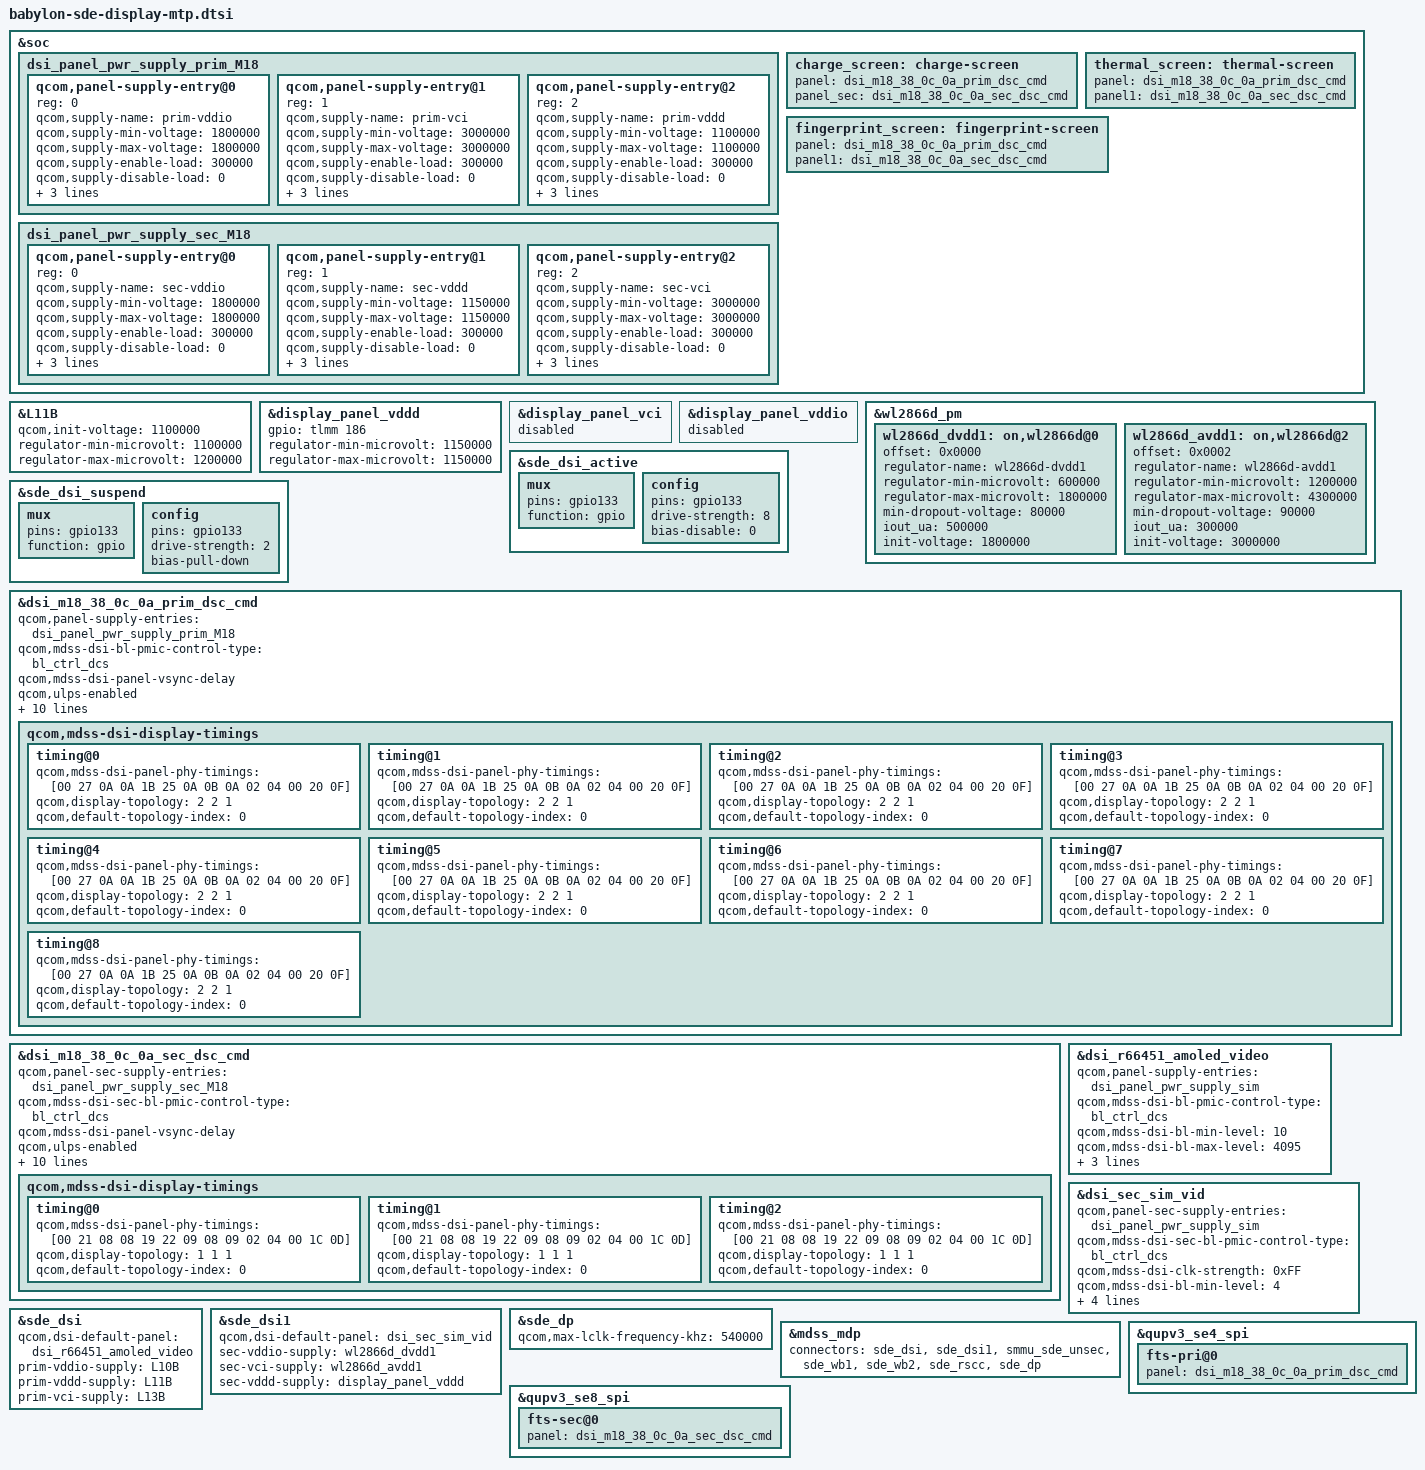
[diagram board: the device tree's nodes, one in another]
#include "kalama-sde-display.dtsi"
#include "dsi-panel-m18-38-0c-0a-prim-dsc-cmd.dtsi"
#include "dsi-panel-m18-38-0c-0a-sec-dsc-cmd.dtsi"

&soc {
	dsi_panel_pwr_supply_prim_M18: dsi_panel_pwr_supply_prim_M18 {
		qcom,panel-supply-entry@0 {
			reg = <0>;
			qcom,supply-name = "prim-vddio";
			qcom,supply-min-voltage = <1800000>;
			qcom,supply-max-voltage = <1800000>;
			qcom,supply-enable-load = <300000>;
			qcom,supply-disable-load = <0>;
			qcom,supply-post-on-sleep = <1>;
			qcom,supply-post-off-sleep = <0>;
			qcom,supply-pre-off-sleep = <15>;
		};
		qcom,panel-supply-entry@1 {
			reg = <1>;
			qcom,supply-name = "prim-vci";
			qcom,supply-min-voltage = <3000000>;
			qcom,supply-max-voltage = <3000000>;
			qcom,supply-enable-load = <300000>;
			qcom,supply-disable-load = <0>;
			qcom,supply-post-on-sleep = <1>;
			qcom,supply-post-off-sleep = <0>;
			qcom,supply-pre-off-sleep = <15>;
		};
		qcom,panel-supply-entry@2 {
			reg = <2>;
			qcom,supply-name = "prim-vddd";
			qcom,supply-min-voltage = <1100000>;
			qcom,supply-max-voltage = <1100000>;
			qcom,supply-enable-load = <300000>;
			qcom,supply-disable-load = <0>;
			qcom,supply-post-on-sleep = <1>;
			qcom,supply-post-off-sleep = <0>;
			qcom,supply-pre-off-sleep = <15>;
		};
	};

	dsi_panel_pwr_supply_sec_M18: dsi_panel_pwr_supply_sec_M18 {
		qcom,panel-supply-entry@0 {
			reg = <0>;
			qcom,supply-name = "sec-vddio";
			qcom,supply-min-voltage = <1800000>;
			qcom,supply-max-voltage = <1800000>;
			qcom,supply-enable-load = <300000>;
			qcom,supply-disable-load = <0>;
			qcom,supply-post-on-sleep = <1>;
			qcom,supply-post-off-sleep = <0>;
			qcom,supply-pre-off-sleep = <15>;
		};
		qcom,panel-supply-entry@1 {
			reg = <1>;
			qcom,supply-name = "sec-vddd";
			qcom,supply-min-voltage = <1150000>;
			qcom,supply-max-voltage = <1150000>;
			qcom,supply-enable-load = <300000>;
			qcom,supply-disable-load = <0>;
			qcom,supply-post-on-sleep = <1>;
			qcom,supply-post-off-sleep = <0>;
			qcom,supply-pre-off-sleep = <15>;
		};
		qcom,panel-supply-entry@2 {
			reg = <2>;
			qcom,supply-name = "sec-vci";
			qcom,supply-min-voltage = <3000000>;
			qcom,supply-max-voltage = <3000000>;
			qcom,supply-enable-load = <300000>;
			qcom,supply-disable-load = <0>;
			qcom,supply-post-on-sleep = <1>;
			qcom,supply-post-off-sleep = <0>;
			qcom,supply-pre-off-sleep = <15>;
		};

	};
};

&L11B {
	qcom,init-voltage = <1100000>;
	regulator-min-microvolt = <1100000>;
	regulator-max-microvolt = <1200000>;
};

&display_panel_vddd {
	gpio = <&tlmm 186 0>;
	regulator-min-microvolt = <1150000>;
	regulator-max-microvolt = <1150000>;
};

&display_panel_vci {
	status = "disabled";
};

&display_panel_vddio {
	status = "disabled";
};

&wl2866d_pm {
	wl2866d_dvdd1:on,wl2866d@0{
		offset = /bits/ 16 <0x0000>;
		regulator-name ="wl2866d-dvdd1";
		regulator-min-microvolt = <600000>;
		regulator-max-microvolt = <1800000>;
		min-dropout-voltage = <80000>;
		iout_ua = <500000>;
		init-voltage = <1800000>;
	};

	wl2866d_avdd1:on,wl2866d@2{
		offset = /bits/ 16 <0x0002>;
		regulator-name ="wl2866d-avdd1";
		regulator-min-microvolt = <1200000>;
		regulator-max-microvolt = <4300000>;
		min-dropout-voltage = <90000>;
		iout_ua = <300000>;
		init-voltage = <3000000>;
	};
};

&sde_dsi_active {
	mux {
		pins = "gpio133";
		function = "gpio";
	};

	config {
		pins = "gpio133";
		drive-strength = <8>;   /* 8 mA */
		bias-disable = <0>;   /* no pull */
	};
};

&sde_dsi_suspend {
	mux {
		pins = "gpio133";
		function = "gpio";
	};

	config {
		pins = "gpio133";
		drive-strength = <2>;   /* 2 mA */
		bias-pull-down;         /* PULL DOWN */
	};
};

&dsi_m18_38_0c_0a_prim_dsc_cmd {
	qcom,panel-supply-entries = <&dsi_panel_pwr_supply_prim_M18>;
	qcom,mdss-dsi-bl-pmic-control-type = "bl_ctrl_dcs";
	qcom,mdss-dsi-panel-vsync-delay;
	qcom,ulps-enabled;
	qcom,dsi-select-clocks = "pll_byte_clk0", "pll_dsi_clk0";
	qcom,mdss-dsi-clk-strength = <0xFF>;
	qcom,mdss-dsi-deemph-eq-strength = <0x88>;
	qcom,mdss-dsi-bl-min-level = <4>;
	qcom,mdss-dsi-bl-max-level = <4095>;
	qcom,mdss-brightness-max-level = <4095>;
	qcom,mdss-brightness-init-level = <307>;
	qcom,mdss-dsi-bl-inverted-dbv;
	qcom,platform-reset-gpio = <&tlmm 133 0>;

	qcom,mdss-dsi-display-timings {
		/* 60hz */
		timing@0{
			qcom,mdss-dsi-panel-phy-timings = [00 27 0A 0A 1B 25 0A
				0B 0A 02 04 00 20 0F];
			qcom,display-topology = <2 2 1>;
			qcom,default-topology-index = <0>;
		};
		/* 120hz */
		timing@1{
			qcom,mdss-dsi-panel-phy-timings = [00 27 0A 0A 1B 25 0A
				0B 0A 02 04 00 20 0F];
			qcom,display-topology = <2 2 1>;
			qcom,default-topology-index = <0>;
		};
		/* 40hz */
		timing@2{
			qcom,mdss-dsi-panel-phy-timings = [00 27 0A 0A 1B 25 0A
				0B 0A 02 04 00 20 0F];
			qcom,display-topology = <2 2 1>;
			qcom,default-topology-index = <0>;
		};
		/* 30hz */
		timing@3{
			qcom,mdss-dsi-panel-phy-timings = [00 27 0A 0A 1B 25 0A
				0B 0A 02 04 00 20 0F];
			qcom,display-topology = <2 2 1>;
			qcom,default-topology-index = <0>;
		};
		/* 24hz */
		timing@4{
			qcom,mdss-dsi-panel-phy-timings = [00 27 0A 0A 1B 25 0A
				0B 0A 02 04 00 20 0F];
			qcom,display-topology = <2 2 1>;
			qcom,default-topology-index = <0>;
		};
		/* 10hz */
		timing@5{
			qcom,mdss-dsi-panel-phy-timings = [00 27 0A 0A 1B 25 0A
				0B 0A 02 04 00 20 0F];
			qcom,display-topology = <2 2 1>;
			qcom,default-topology-index = <0>;
		};
		/* 1hz */
		timing@6{
			qcom,mdss-dsi-panel-phy-timings = [00 27 0A 0A 1B 25 0A
				0B 0A 02 04 00 20 0F];
			qcom,display-topology = <2 2 1>;
			qcom,default-topology-index = <0>;
		};
		/* 120hz to 1hz auto mode */
		timing@7{
			qcom,mdss-dsi-panel-phy-timings = [00 27 0A 0A 1B 25 0A
				0B 0A 02 04 00 20 0F];
			qcom,display-topology = <2 2 1>;
			qcom,default-topology-index = <0>;
		};
		/* 60hz to 1hz auto mode */
		timing@8{
			qcom,mdss-dsi-panel-phy-timings = [00 27 0A 0A 1B 25 0A
				0B 0A 02 04 00 20 0F];
			qcom,display-topology = <2 2 1>;
			qcom,default-topology-index = <0>;
		};
	};
};

&dsi_m18_38_0c_0a_sec_dsc_cmd {
	qcom,panel-sec-supply-entries = <&dsi_panel_pwr_supply_sec_M18>;
	qcom,mdss-dsi-sec-bl-pmic-control-type = "bl_ctrl_dcs";
	qcom,mdss-dsi-panel-vsync-delay;
	qcom,ulps-enabled;
	qcom,dsi-select-sec-clocks = "pll_byte_clk1", "pll_dsi_clk1";
	qcom,mdss-dsi-clk-strength = <0xFF>;
	qcom,mdss-dsi-deemph-eq-strength = <0x88>;
	qcom,mdss-dsi-bl-min-level = <4>;
	qcom,mdss-dsi-bl-max-level = <4095>;
	qcom,mdss-brightness-max-level = <4095>;
	qcom,mdss-brightness-init-level = <307>;
	qcom,mdss-dsi-bl-inverted-dbv;
	qcom,platform-sec-reset-gpio = <&tlmm 178 0>;

	qcom,mdss-dsi-display-timings {
		/* 60hz */
		timing@0{
			qcom,mdss-dsi-panel-phy-timings = [00 21 08 08 19 22 09
				08 09 02 04 00 1C 0D];
			qcom,display-topology = <1 1 1>;
			qcom,default-topology-index = <0>;
		};
		timing@1{
			qcom,mdss-dsi-panel-phy-timings = [00 21 08 08 19 22 09
				08 09 02 04 00 1C 0D];
			qcom,display-topology = <1 1 1>;
			qcom,default-topology-index = <0>;
		};
		timing@2{
			qcom,mdss-dsi-panel-phy-timings = [00 21 08 08 19 22 09
				08 09 02 04 00 1C 0D];
			qcom,display-topology = <1 1 1>;
			qcom,default-topology-index = <0>;
		};
	};
};

&dsi_r66451_amoled_video {
	qcom,panel-supply-entries = <&dsi_panel_pwr_supply_sim>;
	qcom,mdss-dsi-bl-pmic-control-type = "bl_ctrl_dcs";
	qcom,mdss-dsi-bl-min-level = <10>;
	qcom,mdss-dsi-bl-max-level = <4095>;
	qcom,mdss-brightness-max-level = <8191>;
	qcom,mdss-dsi-bl-inverted-dbv;
	qcom,platform-reset-gpio = <&tlmm 133 0>;
	/delete-property/qcom,esd-check-enabled;
};

&dsi_sec_sim_vid {
	qcom,panel-sec-supply-entries = <&dsi_panel_pwr_supply_sim>;
	qcom,mdss-dsi-sec-bl-pmic-control-type = "bl_ctrl_dcs";
	qcom,mdss-dsi-clk-strength = <0xFF>;
	qcom,mdss-dsi-bl-min-level = <4>;
	qcom,mdss-dsi-bl-max-level = <4095>;
	qcom,mdss-brightness-max-level = <8191>;
	qcom,mdss-dsi-bl-inverted-dbv;
	qcom,platform-sec-reset-gpio = <&tlmm 178 0>;
};


&sde_dsi {
	qcom,dsi-default-panel = <&dsi_r66451_amoled_video>;

	prim-vddio-supply = <&L10B>;
	prim-vddd-supply = <&L11B>;
	prim-vci-supply = <&L13B>;
};

&sde_dsi1 {
	qcom,dsi-default-panel = <&dsi_sec_sim_vid>;

	sec-vddio-supply = <&wl2866d_dvdd1>;
	sec-vci-supply = <&wl2866d_avdd1>;
	sec-vddd-supply = <&display_panel_vddd>;
};

&sde_dp {
	qcom,max-lclk-frequency-khz = <540000>;
	status = "ok";
};

&mdss_mdp {
	connectors = <&sde_dsi &sde_dsi1 &smmu_sde_unsec &sde_wb1 &sde_wb2 &sde_rscc &sde_dp>;
};

&qupv3_se4_spi {
	fts-pri@0 {
		panel = <&dsi_m18_38_0c_0a_prim_dsc_cmd>;
	};
};

&qupv3_se8_spi {
	fts-sec@0 {
		panel = <&dsi_m18_38_0c_0a_sec_dsc_cmd>;
	};
};

&soc {
	charge_screen: charge-screen {
		panel  = <&dsi_m18_38_0c_0a_prim_dsc_cmd>;
		panel_sec = <&dsi_m18_38_0c_0a_sec_dsc_cmd>;
	};
	thermal_screen: thermal-screen {
		panel = <&dsi_m18_38_0c_0a_prim_dsc_cmd>;
		panel1 = <&dsi_m18_38_0c_0a_sec_dsc_cmd>;
	};
	fingerprint_screen: fingerprint-screen {
                panel = <&dsi_m18_38_0c_0a_prim_dsc_cmd>;
                panel1 = <&dsi_m18_38_0c_0a_sec_dsc_cmd>;
        };
};
